AUTOSAR XML (schema 4-3-0)
package /ComponentTypes
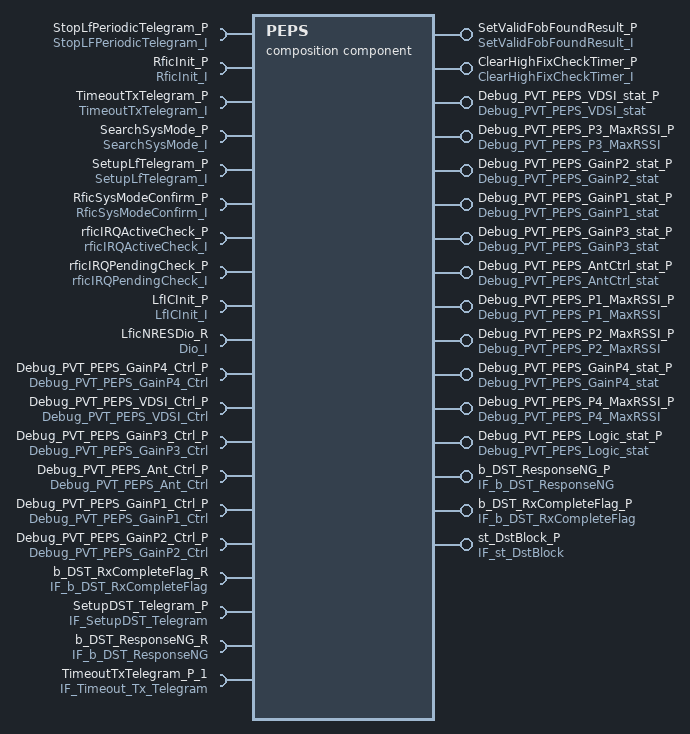
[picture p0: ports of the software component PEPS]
  composition sw component type PEPS
    9 x require port:
      StopLfPeriodicTelegram_P: client-com-spec=CS, required-interface=StopLFPeriodicTelegram_I
      RficInit_P: client-com-spec=CS, required-interface=RficInit_I
      TimeoutTxTelegram_P: client-com-spec=CS, required-interface=TimeoutTxTelegram_I
      SearchSysMode_P: client-com-spec=CS, required-interface=SearchSysMode_I
      SetupLfTelegram_P: client-com-spec=CS, required-interface=SetupLfTelegram_I
      RficSysModeConfirm_P: nonqueued-receiver-com-spec{data-element=SR_RficSysModeConfirm, filter=data-filter-type=ALWAYS, init-value=0}, required-interface=RficSysModeConfirm_I
      rficIRQActiveCheck_P: client-com-spec=CS, required-interface=rficIRQActiveCheck_I
      rficIRQPendingCheck_P: client-com-spec=CS, required-interface=rficIRQPendingCheck_I
      LfICInit_P: client-com-spec=CS, required-interface=LfICInit_I
    provide port SetValidFobFoundResult_P: server-com-spec{operation=CS, queue-length=1}, provided-interface=SetValidFobFoundResult_I
    require port LficNRESDio_R: required-com-specs=[Read, Write], required-interface=Dio_I
    11 x provide port:
      ClearHighFixCheckTimer_P: server-com-spec{operation=CS, queue-length=1}, provided-interface=ClearHighFixCheckTimer_I
      Debug_PVT_PEPS_VDSI_stat_P: nonqueued-sender-com-spec{data-element=Debug_PVT_PEPS_VDSI_stat, init-value=0}, provided-interface=Debug_PVT_PEPS_VDSI_stat
      Debug_PVT_PEPS_P3_MaxRSSI_P: nonqueued-sender-com-spec{data-element=Debug_PVT_PEPS_P3_MaxRSSI, init-value=0}, provided-interface=Debug_PVT_PEPS_P3_MaxRSSI
      Debug_PVT_PEPS_GainP2_stat_P: nonqueued-sender-com-spec{data-element=Debug_PVT_PEPS_GainP2_stat, init-value=0}, provided-interface=Debug_PVT_PEPS_GainP2_stat
      Debug_PVT_PEPS_GainP1_stat_P: nonqueued-sender-com-spec{data-element=Debug_PVT_PEPS_GainP1_stat, init-value=0}, provided-interface=Debug_PVT_PEPS_GainP1_stat
      Debug_PVT_PEPS_GainP3_stat_P: nonqueued-sender-com-spec{data-element=Debug_PVT_PEPS_GainP3_stat, init-value=0}, provided-interface=Debug_PVT_PEPS_GainP3_stat
      Debug_PVT_PEPS_AntCtrl_stat_P: nonqueued-sender-com-spec{data-element=Debug_PVT_PEPS_AntCtrl_stat, init-value=0}, provided-interface=Debug_PVT_PEPS_AntCtrl_stat
      Debug_PVT_PEPS_P1_MaxRSSI_P: nonqueued-sender-com-spec{data-element=Debug_PVT_PEPS_P1_MaxRSSI, init-value=0}, provided-interface=Debug_PVT_PEPS_P1_MaxRSSI
      Debug_PVT_PEPS_P2_MaxRSSI_P: nonqueued-sender-com-spec{data-element=Debug_PVT_PEPS_P2_MaxRSSI, init-value=0}, provided-interface=Debug_PVT_PEPS_P2_MaxRSSI
      Debug_PVT_PEPS_GainP4_stat_P: nonqueued-sender-com-spec{data-element=Debug_PVT_PEPS_GainP4_stat, init-value=0}, provided-interface=Debug_PVT_PEPS_GainP4_stat
      Debug_PVT_PEPS_P4_MaxRSSI_P: nonqueued-sender-com-spec{data-element=Debug_PVT_PEPS_P4_MaxRSSI, init-value=0}, provided-interface=Debug_PVT_PEPS_P4_MaxRSSI
    6 x require port:
      Debug_PVT_PEPS_GainP4_Ctrl_P: nonqueued-receiver-com-spec{data-element=Debug_PVT_PEPS_GainP4_Ctrl, filter=data-filter-type=ALWAYS, init-value=0}, required-interface=Debug_PVT_PEPS_GainP4_Ctrl
      Debug_PVT_PEPS_VDSI_Ctrl_P: nonqueued-receiver-com-spec{data-element=Debug_PVT_PEPS_VDSI_Ctrl, filter=data-filter-type=ALWAYS, init-value=0}, required-interface=Debug_PVT_PEPS_VDSI_Ctrl
      Debug_PVT_PEPS_GainP3_Ctrl_P: nonqueued-receiver-com-spec{data-element=Debug_PVT_PEPS_GainP3_Ctrl, filter=data-filter-type=ALWAYS, init-value=0}, required-interface=Debug_PVT_PEPS_GainP3_Ctrl
      Debug_PVT_PEPS_Ant_Ctrl_P: nonqueued-receiver-com-spec{data-element=Debug_PVT_PEPS_Ant_Ctrl, filter=data-filter-type=ALWAYS, init-value=0}, required-interface=Debug_PVT_PEPS_Ant_Ctrl
      Debug_PVT_PEPS_GainP1_Ctrl_P: nonqueued-receiver-com-spec{data-element=Debug_PVT_PEPS_GainP1_Ctrl, filter=data-filter-type=ALWAYS, init-value=0}, required-interface=Debug_PVT_PEPS_GainP1_Ctrl
      Debug_PVT_PEPS_GainP2_Ctrl_P: nonqueued-receiver-com-spec{data-element=Debug_PVT_PEPS_GainP2_Ctrl, filter=data-filter-type=ALWAYS, init-value=0}, required-interface=Debug_PVT_PEPS_GainP2_Ctrl
    4 x provide port:
      Debug_PVT_PEPS_Logic_stat_P: nonqueued-sender-com-spec{data-element=Debug_PVT_PEPS_Logic_stat, init-value=0}, provided-interface=Debug_PVT_PEPS_Logic_stat
      b_DST_ResponseNG_P: nonqueued-sender-com-spec{data-element=SR, init-value=0}, provided-interface=IF_b_DST_ResponseNG
      b_DST_RxCompleteFlag_P: nonqueued-sender-com-spec{data-element=SR, init-value=0}, provided-interface=IF_b_DST_RxCompleteFlag
      st_DstBlock_P: provided-interface=IF_st_DstBlock
        provided-com-specs:
          data-element=security_key_number, init-value=[0]
          data-element=write_fob_number, init-value=0
          data-element=encryption, init-value=[0]
          data-element=challenge, init-value=[0]
          data-element=vehicle_serial, init-value=[0]
    4 x require port:
      b_DST_RxCompleteFlag_R: nonqueued-receiver-com-spec{data-element=SR, filter=data-filter-type=ALWAYS, init-value=0}, required-interface=IF_b_DST_RxCompleteFlag
      SetupDST_Telegram_P: client-com-spec=CS, required-interface=IF_SetupDST_Telegram
      b_DST_ResponseNG_R: nonqueued-receiver-com-spec{data-element=SR, filter=data-filter-type=ALWAYS, init-value=0}, required-interface=IF_b_DST_ResponseNG
      TimeoutTxTelegram_P_1: client-com-spec=CS, required-interface=IF_Timeout_Tx_Telegram
    component Telegram: type=Telegram
    component TP: type=TP
    delegate Telegram.StopLfPeriodicTelegram_P <-> outer port StopLfPeriodicTelegram_P
    delegate Telegram.RficInit_P <-> outer port RficInit_P
    delegate Telegram.TimeoutTxTelegram_P <-> outer port TimeoutTxTelegram_P
    delegate Telegram.SearchSysMode_P <-> outer port SearchSysMode_P
    delegate Telegram.SetupLfTelegram_P <-> outer port SetupLfTelegram_P
    delegate Telegram.RficSysModeConfirm_P <-> outer port RficSysModeConfirm_P
    delegate Telegram.rficIRQActiveCheck_P <-> outer port rficIRQActiveCheck_P
    delegate Telegram.rficIRQPendingCheck_P <-> outer port rficIRQPendingCheck_P
    delegate Telegram.LfICInit_P <-> outer port LfICInit_P
    delegate Telegram.SetValidFobFoundResult_P <-> outer port SetValidFobFoundResult_P
    delegate Telegram.LficNRESDio_R <-> outer port LficNRESDio_R
    delegate Telegram.ClearHighFixCheckTimer_P <-> outer port ClearHighFixCheckTimer_P
    delegate Telegram.Debug_PVT_PEPS_VDSI_stat_P <-> outer port Debug_PVT_PEPS_VDSI_stat_P
    delegate Telegram.Debug_PVT_PEPS_P3_MaxRSSI_P <-> outer port Debug_PVT_PEPS_P3_MaxRSSI_P
    delegate Telegram.Debug_PVT_PEPS_GainP2_stat_P <-> outer port Debug_PVT_PEPS_GainP2_stat_P
    delegate Telegram.Debug_PVT_PEPS_GainP1_stat_P <-> outer port Debug_PVT_PEPS_GainP1_stat_P
    delegate Telegram.Debug_PVT_PEPS_GainP3_stat_P <-> outer port Debug_PVT_PEPS_GainP3_stat_P
    delegate Telegram.Debug_PVT_PEPS_AntCtrl_stat_P <-> outer port Debug_PVT_PEPS_AntCtrl_stat_P
    delegate Telegram.Debug_PVT_PEPS_P1_MaxRSSI_P <-> outer port Debug_PVT_PEPS_P1_MaxRSSI_P
    delegate Telegram.Debug_PVT_PEPS_P2_MaxRSSI_P <-> outer port Debug_PVT_PEPS_P2_MaxRSSI_P
    delegate Telegram.Debug_PVT_PEPS_GainP4_stat_P <-> outer port Debug_PVT_PEPS_GainP4_stat_P
    delegate Telegram.Debug_PVT_PEPS_P4_MaxRSSI_P <-> outer port Debug_PVT_PEPS_P4_MaxRSSI_P
    delegate Telegram.Debug_PVT_PEPS_GainP4_Ctrl_P <-> outer port Debug_PVT_PEPS_GainP4_Ctrl_P
    delegate Telegram.Debug_PVT_PEPS_VDSI_Ctrl_P <-> outer port Debug_PVT_PEPS_VDSI_Ctrl_P
    delegate Telegram.Debug_PVT_PEPS_GainP3_Ctrl_P <-> outer port Debug_PVT_PEPS_GainP3_Ctrl_P
    delegate Telegram.Debug_PVT_PEPS_Ant_Ctrl_P <-> outer port Debug_PVT_PEPS_Ant_Ctrl_P
    delegate Telegram.Debug_PVT_PEPS_GainP1_Ctrl_P <-> outer port Debug_PVT_PEPS_GainP1_Ctrl_P
    delegate Telegram.Debug_PVT_PEPS_GainP2_Ctrl_P <-> outer port Debug_PVT_PEPS_GainP2_Ctrl_P
    delegate Telegram.Debug_PVT_PEPS_Logic_stat_P <-> outer port Debug_PVT_PEPS_Logic_stat_P
    delegate TP.b_DST_ResponseNG_P <-> outer port b_DST_ResponseNG_P
    delegate TP.b_DST_RxCompleteFlag_P <-> outer port b_DST_RxCompleteFlag_P
    delegate TP.st_DstBlock_P <-> outer port st_DstBlock_P
    delegate TP.b_DST_RxCompleteFlag_R <-> outer port b_DST_RxCompleteFlag_R
    delegation sw connector Timeout_Tx_Telegram_P_TP_Timeout_Tx_Telegram_P: inner-port=TP.TimeoutTxTelegram_P
    delegate TP.SetupDST_Telegram_P <-> outer port SetupDST_Telegram_P
    delegate TP.b_DST_ResponseNG_R <-> outer port b_DST_ResponseNG_R
    delegate TP.TimeoutTxTelegram_P <-> outer port TimeoutTxTelegram_P_1
